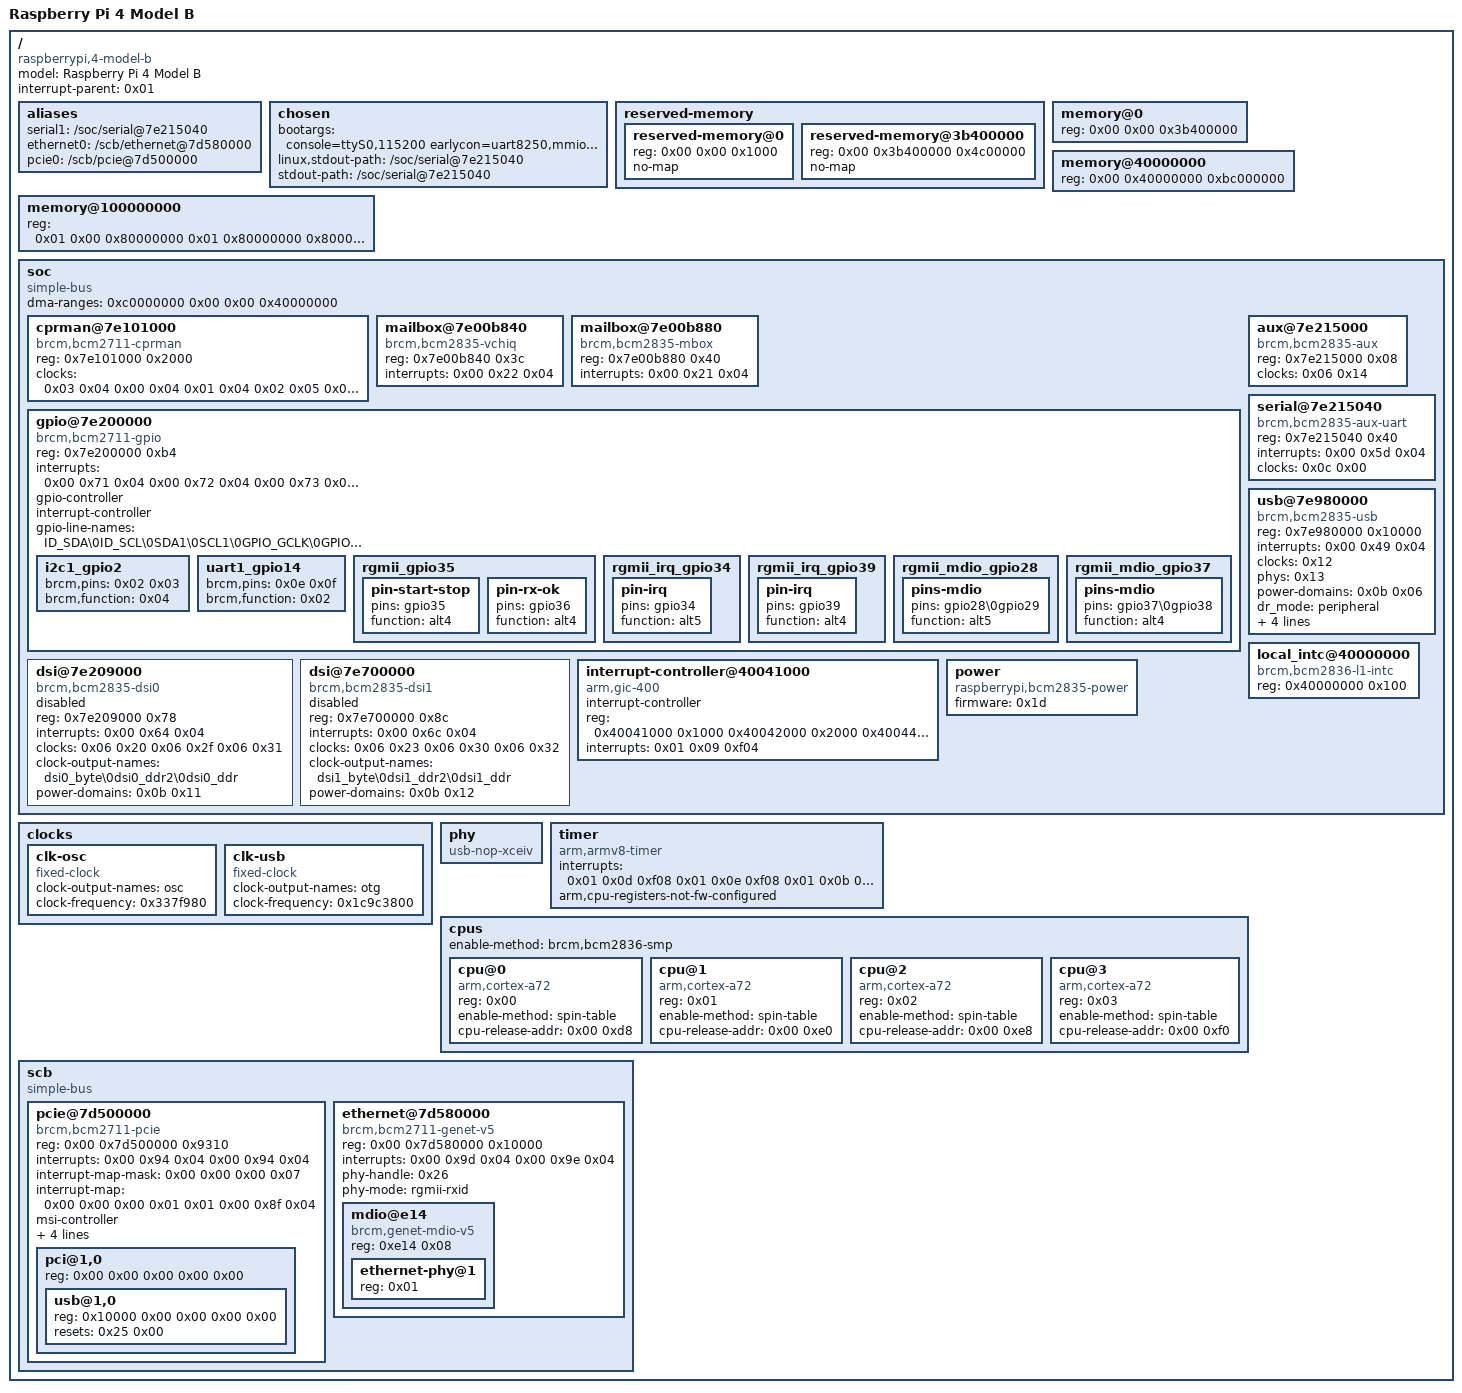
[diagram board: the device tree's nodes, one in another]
/dts-v1/;

/ {
	compatible = "raspberrypi,4-model-b\0brcm,bcm2711";
	model = "Raspberry Pi 4 Model B";
	#address-cells = <0x02>;
	#size-cells = <0x01>;
	interrupt-parent = <0x01>;

	aliases {
		serial1 = "/soc/serial@7e215040";
		ethernet0 = "/scb/ethernet@7d580000";
		pcie0 = "/scb/pcie@7d500000";
	};

	chosen {
		bootargs = "console=ttyS0,115200 earlycon=uart8250,mmio32,0xfe215040 8250.nr_uarts=1 root=/dev/nfs rootfstype=nfs ip=dhcp rw debug loglevel=7 pci=nomsi initcall_blacklist=clk_disable_unused nosmp maxcpus=1";
		linux,stdout-path = "/soc/serial@7e215040";
		stdout-path = "/soc/serial@7e215040";
	};

	reserved-memory {
		#address-cells = <0x02>;
		#size-cells = <0x01>;
		ranges;

		reserved-memory@0 {
			reg = <0x00 0x00 0x1000>;
			no-map;
		};

		reserved-memory@3b400000 {
			reg = <0x00 0x3b400000 0x4c00000>;
			no-map;
		};
	};

	memory@0 {
		device_type = "memory";
		reg = <0x00 0x00 0x3b400000>;
	};

	memory@40000000 {
		device_type = "memory";
		reg = <0x00 0x40000000 0xbc000000>;
	};

	memory@100000000 {
		device_type = "memory";
		reg = <0x01 0x00 0x80000000 0x01 0x80000000 0x80000000>;
	};

	soc {
		compatible = "simple-bus";
		#address-cells = <0x01>;
		#size-cells = <0x01>;
		ranges = <0x7e000000 0x00 0xfe000000 0x1800000 0x7c000000 0x00 0xfc000000 0x2000000 0x40000000 0x00 0xff800000 0x800000>;
		dma-ranges = <0xc0000000 0x00 0x00 0x40000000>;

		cprman@7e101000 {
			compatible = "brcm,bcm2711-cprman";
			#clock-cells = <0x01>;
			reg = <0x7e101000 0x2000>;
			clocks = <0x03 0x04 0x00 0x04 0x01 0x04 0x02 0x05 0x00 0x05 0x01 0x05 0x02>;
			phandle = <0x06>;
		};

		mailbox@7e00b840 {
			compatible = "brcm,bcm2835-vchiq";
			reg = <0x7e00b840 0x3c>;
			interrupts = <0x00 0x22 0x04>;
		};

		mailbox@7e00b880 {
			compatible = "brcm,bcm2835-mbox";
			reg = <0x7e00b880 0x40>;
			interrupts = <0x00 0x21 0x04>;
			#mbox-cells = <0x00>;
			phandle = <0x1c>;
		};

		gpio@7e200000 {
			compatible = "brcm,bcm2711-gpio";
			reg = <0x7e200000 0xb4>;
			interrupts = <0x00 0x71 0x04 0x00 0x72 0x04 0x00 0x73 0x04 0x00 0x74 0x04>;
			gpio-controller;
			#gpio-cells = <0x02>;
			interrupt-controller;
			#interrupt-cells = <0x02>;
			pinctrl-names = "default";
			gpio-line-names = "ID_SDA\0ID_SCL\0SDA1\0SCL1\0GPIO_GCLK\0GPIO5\0GPIO6\0SPI_CE1_N\0SPI_CE0_N\0SPI_MISO\0SPI_MOSI\0SPI_SCLK\0GPIO12\0GPIO13\0TXD1\0RXD1\0GPIO16\0GPIO17\0GPIO18\0GPIO19\0GPIO20\0GPIO21\0GPIO22\0GPIO23\0GPIO24\0GPIO25\0GPIO26\0GPIO27\0RGMII_MDIO\0RGMIO_MDC\0CTS0\0RTS0\0TXD0\0RXD0\0SD1_CLK\0SD1_CMD\0SD1_DATA0\0SD1_DATA1\0SD1_DATA2\0SD1_DATA3\0PWM0_MISO\0PWM1_MOSI\0STATUS_LED_G_CLK\0SPIFLASH_CE_N\0SDA0\0SCL0\0RGMII_RXCLK\0RGMII_RXCTL\0RGMII_RXD0\0RGMII_RXD1\0RGMII_RXD2\0RGMII_RXD3\0RGMII_TXCLK\0RGMII_TXCTL\0RGMII_TXD0\0RGMII_TXD1\0RGMII_TXD2\0RGMII_TXD3";
			phandle = <0x27>;

			i2c1_gpio2 {
				brcm,pins = <0x02 0x03>;
				brcm,function = <0x04>;
				phandle = <0x11>;
			};

			uart1_gpio14 {
				brcm,pins = <0x0e 0x0f>;
				brcm,function = <0x02>;
				phandle = <0x0d>;
			};

			rgmii_gpio35 {

				pin-start-stop {
					pins = "gpio35";
					function = "alt4";
				};

				pin-rx-ok {
					pins = "gpio36";
					function = "alt4";
				};
			};

			rgmii_irq_gpio34 {

				pin-irq {
					pins = "gpio34";
					function = "alt5";
				};
			};

			rgmii_irq_gpio39 {

				pin-irq {
					pins = "gpio39";
					function = "alt4";
				};
			};

			rgmii_mdio_gpio28 {

				pins-mdio {
					pins = "gpio28\0gpio29";
					function = "alt5";
				};
			};

			rgmii_mdio_gpio37 {

				pins-mdio {
					pins = "gpio37\0gpio38";
					function = "alt4";
				};
			};
		};

		dsi@7e209000 {
			compatible = "brcm,bcm2835-dsi0";
			reg = <0x7e209000 0x78>;
			interrupts = <0x00 0x64 0x04>;
			#address-cells = <0x01>;
			#size-cells = <0x00>;
			#clock-cells = <0x01>;
			clocks = <0x06 0x20 0x06 0x2f 0x06 0x31>;
			clock-names = "phy\0escape\0pixel";
			clock-output-names = "dsi0_byte\0dsi0_ddr2\0dsi0_ddr";
			status = "disabled";
			power-domains = <0x0b 0x11>;
			phandle = <0x04>;
		};

		aux@7e215000 {
			compatible = "brcm,bcm2835-aux";
			#clock-cells = <0x01>;
			reg = <0x7e215000 0x08>;
			clocks = <0x06 0x14>;
			phandle = <0x0c>;
		};

		serial@7e215040 {
			compatible = "brcm,bcm2835-aux-uart";
			reg = <0x7e215040 0x40>;
			interrupts = <0x00 0x5d 0x04>;
			clocks = <0x0c 0x00>;
			status = "okay";
		};

		dsi@7e700000 {
			compatible = "brcm,bcm2835-dsi1";
			reg = <0x7e700000 0x8c>;
			interrupts = <0x00 0x6c 0x04>;
			#address-cells = <0x01>;
			#size-cells = <0x00>;
			#clock-cells = <0x01>;
			clocks = <0x06 0x23 0x06 0x30 0x06 0x32>;
			clock-names = "phy\0escape\0pixel";
			clock-output-names = "dsi1_byte\0dsi1_ddr2\0dsi1_ddr";
			status = "disabled";
			power-domains = <0x0b 0x12>;
			phandle = <0x05>;
		};

		usb@7e980000 {
			compatible = "brcm,bcm2835-usb";
			reg = <0x7e980000 0x10000>;
			interrupts = <0x00 0x49 0x04>;
			#address-cells = <0x01>;
			#size-cells = <0x00>;
			clocks = <0x12>;
			clock-names = "otg";
			phys = <0x13>;
			phy-names = "usb2-phy";
			power-domains = <0x0b 0x06>;
			dr_mode = "peripheral";
			g-rx-fifo-size = <0x100>;
			g-np-tx-fifo-size = <0x20>;
			g-tx-fifo-size = <0x100 0x100 0x200 0x200 0x200 0x300 0x300>;
		};

		local_intc@40000000 {
			compatible = "brcm,bcm2836-l1-intc";
			reg = <0x40000000 0x100>;
		};

		interrupt-controller@40041000 {
			interrupt-controller;
			#interrupt-cells = <0x03>;
			compatible = "arm,gic-400";
			reg = <0x40041000 0x1000 0x40042000 0x2000 0x40044000 0x2000 0x40046000 0x2000>;
			interrupts = <0x01 0x09 0xf04>;
			phandle = <0x01>;
		};

		power {
			compatible = "raspberrypi,bcm2835-power";
			firmware = <0x1d>;
			#power-domain-cells = <0x01>;
			phandle = <0x0b>;
		};
	};

	clocks {

		clk-osc {
			compatible = "fixed-clock";
			#clock-cells = <0x00>;
			clock-output-names = "osc";
			clock-frequency = <0x337f980>;
			phandle = <0x03>;
		};

		clk-usb {
			compatible = "fixed-clock";
			#clock-cells = <0x00>;
			clock-output-names = "otg";
			clock-frequency = <0x1c9c3800>;
			phandle = <0x12>;
		};
	};

	phy {
		compatible = "usb-nop-xceiv";
		#phy-cells = <0x00>;
		phandle = <0x13>;
	};

	timer {
		compatible = "arm,armv8-timer";
		interrupts = <0x01 0x0d 0xf08 0x01 0x0e 0xf08 0x01 0x0b 0xf08 0x01 0x0a 0xf08>;
		arm,cpu-registers-not-fw-configured;
	};

	cpus {
		#address-cells = <0x01>;
		#size-cells = <0x00>;
		enable-method = "brcm,bcm2836-smp";

		cpu@0 {
			device_type = "cpu";
			compatible = "arm,cortex-a72";
			reg = <0x00>;
			enable-method = "spin-table";
			cpu-release-addr = <0x00 0xd8>;
			phandle = <0x20>;
		};

		cpu@1 {
			device_type = "cpu";
			compatible = "arm,cortex-a72";
			reg = <0x01>;
			enable-method = "spin-table";
			cpu-release-addr = <0x00 0xe0>;
			phandle = <0x21>;
		};

		cpu@2 {
			device_type = "cpu";
			compatible = "arm,cortex-a72";
			reg = <0x02>;
			enable-method = "spin-table";
			cpu-release-addr = <0x00 0xe8>;
			phandle = <0x22>;
		};

		cpu@3 {
			device_type = "cpu";
			compatible = "arm,cortex-a72";
			reg = <0x03>;
			enable-method = "spin-table";
			cpu-release-addr = <0x00 0xf0>;
			phandle = <0x23>;
		};
	};

	scb {
		compatible = "simple-bus";
		#address-cells = <0x02>;
		#size-cells = <0x01>;
		ranges = <0x00 0x7c000000 0x00 0xfc000000 0x3800000 0x06 0x00 0x06 0x00 0x40000000>;

		pcie@7d500000 {
			compatible = "brcm,bcm2711-pcie";
			reg = <0x00 0x7d500000 0x9310>;
			device_type = "pci";
			#address-cells = <0x03>;
			#interrupt-cells = <0x01>;
			#size-cells = <0x02>;
			interrupts = <0x00 0x94 0x04 0x00 0x94 0x04>;
			interrupt-names = "pcie\0msi";
			interrupt-map-mask = <0x00 0x00 0x00 0x07>;
			interrupt-map = <0x00 0x00 0x00 0x01 0x01 0x00 0x8f 0x04>;
			msi-controller;
			msi-parent = <0x24>;
			ranges = <0x2000000 0x00 0xf8000000 0x06 0x00 0x00 0x4000000>;
			dma-ranges = <0x2000000 0x00 0x00 0x00 0x00 0x00 0xc0000000>;
			brcm,enable-ssc;
			phandle = <0x24>;

			pci@1,0 {
				#address-cells = <0x03>;
				#size-cells = <0x02>;
				ranges;
				reg = <0x00 0x00 0x00 0x00 0x00>;

				usb@1,0 {
					reg = <0x10000 0x00 0x00 0x00 0x00>;
					resets = <0x25 0x00>;
				};
			};
		};

		ethernet@7d580000 {
			compatible = "brcm,bcm2711-genet-v5";
			reg = <0x00 0x7d580000 0x10000>;
			#address-cells = <0x01>;
			#size-cells = <0x01>;
			interrupts = <0x00 0x9d 0x04 0x00 0x9e 0x04>;
			status = "okay";
			phy-handle = <0x26>;
			phy-mode = "rgmii-rxid";

			mdio@e14 {
				compatible = "brcm,genet-mdio-v5";
				reg = <0xe14 0x08>;
				reg-names = "mdio";
				#address-cells = <0x00>;
				#size-cells = <0x01>;

				ethernet-phy@1 {
					reg = <0x01>;
					phandle = <0x26>;
				};
			};
		};
	};
};
